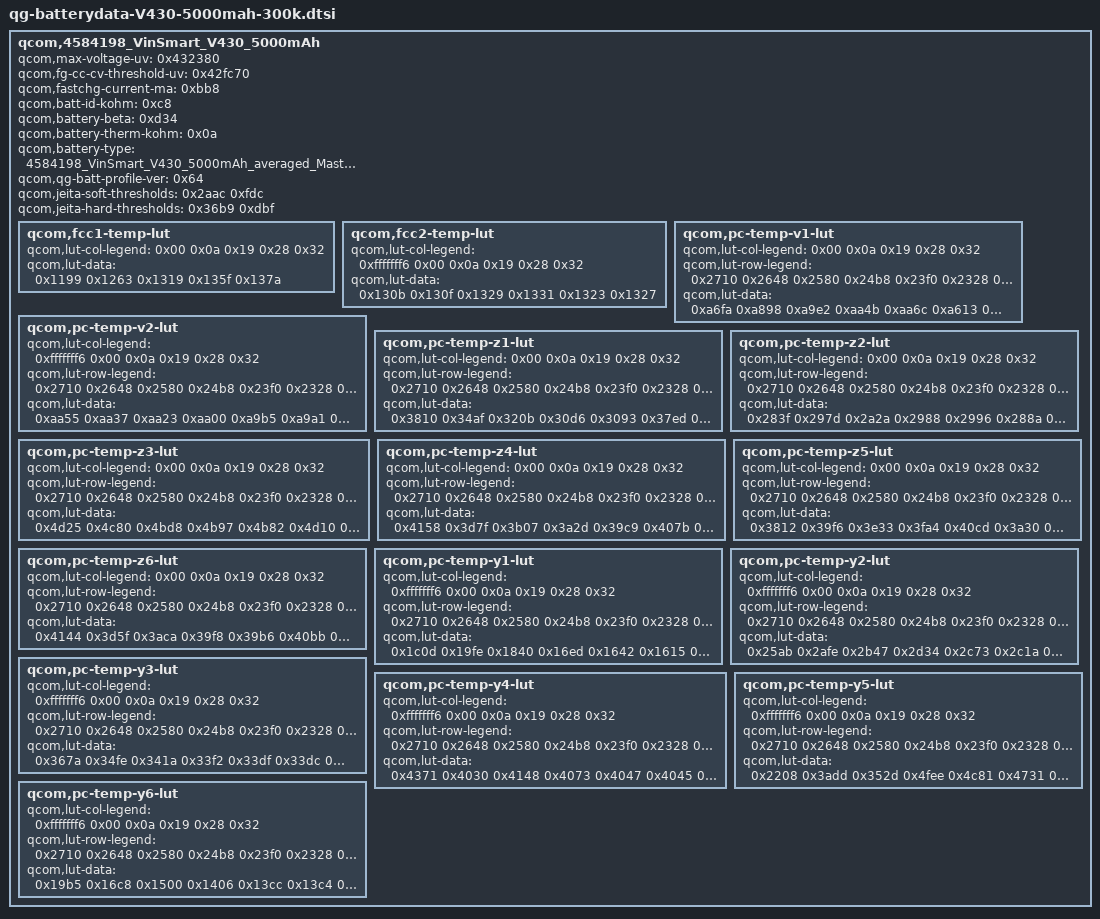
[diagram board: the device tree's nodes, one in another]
qcom,4584198_VinSmart_V430_5000mAh {
	qcom,max-voltage-uv = <0x432380>;
	qcom,fg-cc-cv-threshold-uv = <0x42fc70>;
	qcom,fastchg-current-ma = <0xbb8>;
	qcom,batt-id-kohm = <0xc8>;
	qcom,battery-beta = <0xd34>;
	qcom,battery-therm-kohm = <0x0a>;
	qcom,battery-type = "4584198_VinSmart_V430_5000mAh_averaged_MasterSlave_Jun3rd2020";
	qcom,qg-batt-profile-ver = <0x64>;
	qcom,jeita-soft-thresholds = <0x2aac 0xfdc>;
	qcom,jeita-hard-thresholds = <0x36b9 0xdbf>;

	qcom,fcc1-temp-lut {
		qcom,lut-col-legend = <0x00 0x0a 0x19 0x28 0x32>;
		qcom,lut-data = <0x1199 0x1263 0x1319 0x135f 0x137a>;
	};

	qcom,fcc2-temp-lut {
		qcom,lut-col-legend = <0xfffffff6 0x00 0x0a 0x19 0x28 0x32>;
		qcom,lut-data = <0x130b 0x130f 0x1329 0x1331 0x1323 0x1327>;
	};

	qcom,pc-temp-v1-lut {
		qcom,lut-col-legend = <0x00 0x0a 0x19 0x28 0x32>;
		qcom,lut-row-legend = <0x2710 0x2648 0x2580 0x24b8 0x23f0 0x2328 0x2260 0x2198 0x20d0 0x2008 0x1f40 0x1e78 0x1db0 0x1ce8 0x1c20 0x1b58 0x1a90 0x19c8 0x1900 0x1838 0x1770 0x16a8 0x15e0 0x1518 0x1450 0x1388 0x12c0 0x11f8 0x1130 0x1068 0xfa0 0xed8 0xe10 0xd48 0xc80 0xbb8 0xaf0 0xa28 0x960 0x898 0x7d0 0x708 0x640 0x578 0x4b0 0x3e8 0x384 0x320 0x2bc 0x258 0x1f4 0x190 0x12c 0xc8 0x64 0x00>;
		qcom,lut-data = <0xa6fa 0xa898 0xa9e2 0xaa4b 0xaa6c 0xa613 0xa7ac 0xa8ef 0xa95b 0xa981 0xa533 0xa6c5 0xa7fe 0xa86d 0xa893 0xa45c 0xa5e2 0xa70e 0xa780 0xa7a7 0xa38b 0xa503 0xa623 0xa695 0xa6c0 0xa2c2 0xa429 0xa53b 0xa5ac 0xa5d8 0xa204 0xa355 0xa458 0xa4c6 0xa4f2 0xa152 0xa288 0xa37a 0xa3e3 0xa40e 0xa0a2 0xa1c5 0xa2a1 0xa305 0xa32e 0x9fe5 0xa110 0xa1cd 0xa22a 0xa252 0x9f15 0xa056 0xa105 0xa153 0xa179 0x9e3a 0x9f87 0xa044 0xa080 0xa0a2 0x9d50 0x9ea7 0x9f79 0x9fb1 0x9fd0 0x9c68 0x9dcc 0x9e9c 0x9ee7 0x9f06 0x9bb2 0x9cf2 0x9dc5 0x9e22 0x9e40 0x9b33 0x9c2c 0x9d0a 0x9d67 0x9d84 0x9ace 0x9b97 0x9c60 0x9cbd 0x9cd6 0x9a67 0x9b26 0x9bbf 0x9c13 0x9c2c 0x99ff 0x9ab8 0x9b2a 0x9b59 0x9b75 0x9997 0x9a3b 0x9a91 0x9a91 0x9aaf 0x9934 0x99b8 0x99d3 0x99d3 0x99ee 0x98d2 0x992f 0x98f2 0x991d 0x9938 0x9875 0x98a2 0x9832 0x9876 0x988d 0x981f 0x9812 0x979c 0x97dc 0x97ef 0x97ce 0x9782 0x971f 0x974d 0x975c 0x9781 0x96ec 0x96be 0x96d5 0x96de 0x9736 0x9672 0x9670 0x9673 0x9677 0x96ef 0x9624 0x962c 0x961c 0x961c 0x96a8 0x95e7 0x95ea 0x95ca 0x95c6 0x9661 0x95b8 0x95ad 0x957d 0x9575 0x961e 0x9592 0x9575 0x953a 0x952d 0x95e4 0x9574 0x953f 0x9502 0x94ec 0x95b1 0x9558 0x950e 0x94cf 0x94b2 0x9582 0x9540 0x94e2 0x949a 0x9478 0x9556 0x9526 0x94bb 0x9467 0x9442 0x952c 0x9506 0x9492 0x9434 0x940a 0x9502 0x94de 0x9469 0x9404 0x93d1 0x94d8 0x94ac 0x943a 0x93d1 0x9394 0x94ab 0x9465 0x93f5 0x938a 0x9348 0x946f 0x940c 0x9398 0x932e 0x92ec 0x940b 0x93a5 0x9330 0x92c6 0x9284 0x938c 0x9328 0x92b9 0x9254 0x9210 0x9302 0x929c 0x9234 0x91d4 0x918e 0x9277 0x9201 0x9199 0x9139 0x90f6 0x91f9 0x9187 0x911c 0x90bf 0x9080 0x9191 0x9137 0x90cd 0x9072 0x9036 0x916b 0x911a 0x90b9 0x905b 0x9021 0x9148 0x9107 0x90a6 0x904c 0x9010 0x9123 0x90f4 0x9097 0x9039 0x8ffd 0x90d6 0x90b1 0x905f 0x9000 0x8fbd 0x8ffa 0x8fd2 0x8f6f 0x8efd 0x8ea5 0x8e55 0x8e14 0x8dc3 0x8d50 0x8cf8 0x8c2a 0x8bf0 0x8ba0 0x8b25 0x8acb 0x894d 0x8911 0x88b6 0x8835 0x87db 0x8498 0x846c 0x8420 0x83a9 0x8357 0x7530 0x7530 0x7530 0x7530 0x7530>;
	};

	qcom,pc-temp-v2-lut {
		qcom,lut-col-legend = <0xfffffff6 0x00 0x0a 0x19 0x28 0x32>;
		qcom,lut-row-legend = <0x2710 0x2648 0x2580 0x24b8 0x23f0 0x2328 0x2260 0x2198 0x20d0 0x2008 0x1f40 0x1e78 0x1db0 0x1ce8 0x1c20 0x1b58 0x1a90 0x19c8 0x1900 0x1838 0x1770 0x16a8 0x15e0 0x1518 0x1450 0x1388 0x12c0 0x11f8 0x1130 0x1068 0xfa0 0xed8 0xe10 0xd48 0xc80 0xbb8 0xaf0 0xa28 0x960 0x898 0x7d0 0x708 0x640 0x578 0x4b0 0x3e8 0x384 0x320 0x2bc 0x258 0x1f4 0x190 0x12c 0xc8 0x64 0x00>;
		qcom,lut-data = <0xaa55 0xaa37 0xaa23 0xaa00 0xa9b5 0xa9a1 0xa8a4 0xa8ab 0xa8d5 0xa8d5 0xa89b 0xa893 0xa721 0xa747 0xa7a1 0xa7bd 0xa790 0xa78f 0xa5d5 0xa611 0xa68c 0xa6bb 0xa696 0xa699 0xa4b8 0xa503 0xa595 0xa5cd 0xa5ad 0xa5b1 0xa3b3 0xa40c 0xa4a9 0xa4e7 0xa4cb 0xa4ce 0xa29d 0xa322 0xa3bf 0xa403 0xa3e7 0xa3eb 0xa198 0xa248 0xa2d9 0xa323 0xa307 0xa30b 0xa10f 0xa182 0xa1f6 0xa246 0xa22b 0xa22f 0xa0dc 0xa0d8 0xa10d 0xa16a 0xa152 0xa157 0xa0a5 0xa02d 0xa037 0xa096 0xa07e 0xa083 0x9fb0 0x9f62 0x9f92 0x9fda 0x9fb1 0x9fb4 0x9d96 0x9e7c 0x9f04 0x9f29 0x9eea 0x9ee9 0x9bf7 0x9d7f 0x9e44 0x9e61 0x9e28 0x9e25 0x9b0b 0x9c4d 0x9d0a 0x9d69 0x9d65 0x9d67 0x9a48 0x9b24 0x9bc9 0x9c7a 0x9ca7 0x9cae 0x998c 0x9a51 0x9af7 0x9bcc 0x9bf8 0x9bfe 0x98dd 0x99ac 0x9a56 0x9b3f 0x9b52 0x9b56 0x9831 0x9909 0x99b1 0x9a9a 0x9a9f 0x9aa2 0x977c 0x9859 0x98f8 0x99bf 0x99cd 0x99d4 0x96d0 0x97a8 0x9842 0x98db 0x98f6 0x9903 0x9648 0x96f3 0x97a3 0x9820 0x983a 0x9849 0x95d5 0x9631 0x9714 0x977c 0x978f 0x979c 0x9575 0x9599 0x9691 0x96ec 0x96fb 0x9704 0x9527 0x9540 0x961a 0x9673 0x967f 0x9686 0x94e3 0x94fd 0x95ab 0x9606 0x9612 0x9617 0x94a5 0x94c2 0x953b 0x95a4 0x95af 0x95b3 0x946c 0x948e 0x94ca 0x9549 0x9555 0x9557 0x9436 0x945e 0x946e 0x94f7 0x9503 0x9503 0x93ff 0x9430 0x942d 0x94ab 0x94b9 0x94b8 0x93c7 0x9404 0x93fb 0x9465 0x9476 0x9474 0x9391 0x93d8 0x93d1 0x9422 0x9434 0x9431 0x935d 0x93ab 0x93b1 0x93e4 0x93f6 0x93f4 0x9328 0x937d 0x9391 0x93a7 0x93b5 0x93b2 0x92f1 0x934b 0x936c 0x9371 0x936a 0x935d 0x92b9 0x9316 0x9343 0x933c 0x9318 0x92fa 0x9280 0x92db 0x9315 0x9301 0x92c7 0x929b 0x9249 0x9297 0x92de 0x92c2 0x9278 0x9243 0x9210 0x924b 0x929a 0x927c 0x9228 0x91ed 0x91d7 0x91fa 0x9240 0x9233 0x91d9 0x919c 0x919b 0x91a3 0x91ce 0x91e4 0x918a 0x914e 0x915b 0x914d 0x9161 0x9184 0x912f 0x90f3 0x9115 0x90fe 0x90f8 0x9105 0x90b5 0x9079 0x90c8 0x90b3 0x909a 0x908d 0x9043 0x9008 0x906d 0x906a 0x904c 0x9029 0x8fea 0x8fb1 0x8ffc 0x9012 0x8ff6 0x8ff8 0x8fc4 0x8f90 0x8fb8 0x8fdd 0x8fc4 0x8fe6 0x8fb7 0x8f84 0x8f52 0x8f9f 0x8f88 0x8fcf 0x8fa4 0x8f73 0x8ecd 0x8f52 0x8f3b 0x8faa 0x8f86 0x8f56 0x8e24 0x8ed5 0x8eb4 0x8f4d 0x8f29 0x8ef2 0x8d26 0x8dfc 0x8dd3 0x8e4d 0x8e0f 0x8dbf 0x8bb3 0x8c7b 0x8c6d 0x8c7d 0x8c3e 0x8bec 0x899f 0x8a43 0x8a43 0x8a18 0x89e9 0x898e 0x8673 0x8700 0x8723 0x86db 0x86bb 0x865d 0x8122 0x81dc 0x8227 0x81f1 0x821e 0x81c3 0x743f 0x73d8 0x73b0 0x7393 0x7378 0x736a>;
	};

	qcom,pc-temp-z1-lut {
		qcom,lut-col-legend = <0x00 0x0a 0x19 0x28 0x32>;
		qcom,lut-row-legend = <0x2710 0x2648 0x2580 0x24b8 0x23f0 0x2328 0x2260 0x2198 0x20d0 0x2008 0x1f40 0x1e78 0x1db0 0x1ce8 0x1c20 0x1b58 0x1a90 0x19c8 0x1900 0x1838 0x1770 0x16a8 0x15e0 0x1518 0x1450 0x1388 0x12c0 0x11f8 0x1130 0x1068 0xfa0 0xed8 0xe10 0xd48 0xc80 0xbb8 0xaf0 0xa28 0x960 0x898 0x7d0 0x708 0x640 0x578 0x4b0 0x3e8 0x384 0x320 0x2bc 0x258 0x1f4 0x190 0x12c 0xc8 0x64 0x00>;
		qcom,lut-data = <0x3810 0x34af 0x320b 0x30d6 0x3093 0x37ed 0x34bd 0x3201 0x30d7 0x3099 0x37d6 0x34c2 0x3200 0x30da 0x30a1 0x37d1 0x34b9 0x3200 0x30da 0x30a3 0x37cd 0x34aa 0x31fe 0x30da 0x30a2 0x37cc 0x34a6 0x31f8 0x30da 0x30a4 0x37cf 0x34a9 0x31f3 0x30d9 0x30a8 0x37d1 0x34ad 0x31f0 0x30da 0x30ab 0x37cf 0x34ad 0x31ee 0x30dc 0x30b0 0x37c5 0x34a7 0x31ed 0x30e0 0x30b5 0x37b6 0x34a0 0x31f0 0x30e2 0x30b8 0x37b1 0x3493 0x31f3 0x30e2 0x30ba 0x37b0 0x347c 0x31f3 0x30e2 0x30bc 0x379c 0x346f 0x31ea 0x30e3 0x30be 0x3784 0x3470 0x31e2 0x30e4 0x30c0 0x3768 0x3477 0x31e3 0x30e6 0x30c2 0x3750 0x347f 0x31e9 0x30e9 0x30c5 0x374d 0x3489 0x31f0 0x30ec 0x30c8 0x374a 0x3493 0x31f9 0x30ef 0x30cb 0x3746 0x349c 0x3203 0x30f3 0x30ce 0x3741 0x34a4 0x3209 0x30f6 0x30d1 0x3736 0x34aa 0x320d 0x30fa 0x30d5 0x372b 0x34b1 0x3211 0x30fe 0x30d9 0x372a 0x34b7 0x3215 0x3101 0x30dd 0x372e 0x34be 0x3219 0x3105 0x30e2 0x3732 0x34c8 0x321e 0x3108 0x30e6 0x373b 0x34d0 0x3223 0x310e 0x30eb 0x374c 0x34d4 0x3229 0x3115 0x30ee 0x375b 0x34da 0x3230 0x311a 0x30f2 0x3766 0x34e1 0x3237 0x311e 0x30f6 0x3770 0x34ed 0x323d 0x3123 0x30fa 0x377b 0x34f9 0x3241 0x3127 0x30fe 0x3788 0x34ff 0x3245 0x312b 0x3102 0x3794 0x3505 0x324b 0x312f 0x3106 0x379c 0x350b 0x3251 0x3134 0x3109 0x37a1 0x3511 0x3257 0x3138 0x310d 0x37a8 0x3517 0x3260 0x313d 0x3110 0x37bb 0x351c 0x3268 0x3143 0x3114 0x37d8 0x3524 0x3270 0x3147 0x3118 0x37e8 0x352c 0x3277 0x314b 0x311d 0x37e4 0x3532 0x327d 0x314f 0x3121 0x37dc 0x3539 0x3282 0x3155 0x3125 0x37d9 0x354e 0x3287 0x315b 0x3128 0x37da 0x3570 0x3291 0x3161 0x312c 0x37c9 0x3560 0x329c 0x3166 0x3130 0x37da 0x3559 0x32a6 0x3169 0x3132 0x3804 0x355a 0x32a1 0x316c 0x3132 0x37cf 0x3569 0x32a3 0x316b 0x3133 0x37d6 0x356a 0x32a7 0x316e 0x3135 0x37df 0x356b 0x32ab 0x3174 0x3139 0x37f6 0x3574 0x32b7 0x317b 0x313f 0x3802 0x3586 0x32c6 0x3185 0x3147 0x37ff 0x3595 0x32e0 0x3192 0x3153 0x3803 0x35d5 0x3301 0x31a8 0x3163 0x3803 0x35d5 0x3301 0x31a8 0x3163 0x3803 0x35d5 0x3301 0x31a8 0x3163>;
	};

	qcom,pc-temp-z2-lut {
		qcom,lut-col-legend = <0x00 0x0a 0x19 0x28 0x32>;
		qcom,lut-row-legend = <0x2710 0x2648 0x2580 0x24b8 0x23f0 0x2328 0x2260 0x2198 0x20d0 0x2008 0x1f40 0x1e78 0x1db0 0x1ce8 0x1c20 0x1b58 0x1a90 0x19c8 0x1900 0x1838 0x1770 0x16a8 0x15e0 0x1518 0x1450 0x1388 0x12c0 0x11f8 0x1130 0x1068 0xfa0 0xed8 0xe10 0xd48 0xc80 0xbb8 0xaf0 0xa28 0x960 0x898 0x7d0 0x708 0x640 0x578 0x4b0 0x3e8 0x384 0x320 0x2bc 0x258 0x1f4 0x190 0x12c 0xc8 0x64 0x00>;
		qcom,lut-data = <0x283f 0x297d 0x2a2a 0x2988 0x2996 0x288a 0x2967 0x2a29 0x29cf 0x2993 0x28ba 0x2955 0x2a29 0x29fa 0x29a8 0x28c7 0x2946 0x2a1e 0x2a07 0x29ac 0x28ad 0x2937 0x2a0d 0x2a0e 0x29ab 0x288a 0x2928 0x29f9 0x2a09 0x29a3 0x287d 0x2919 0x29e1 0x29e5 0x2985 0x287e 0x290a 0x29cf 0x29c8 0x296a 0x287f 0x2900 0x29bf 0x29c1 0x295a 0x2881 0x28f8 0x29b6 0x29b8 0x2930 0x2884 0x28f0 0x29c4 0x29b3 0x2913 0x2886 0x28ea 0x29e5 0x29bd 0x291f 0x287d 0x28e4 0x29fa 0x29c9 0x2931 0x2862 0x28e3 0x2a04 0x29cb 0x293e 0x2845 0x28e5 0x2a0a 0x29cc 0x294c 0x282a 0x28e8 0x2a09 0x29cb 0x295a 0x2814 0x28f1 0x2a07 0x29af 0x2970 0x280c 0x2909 0x2a0a 0x298f 0x298b 0x2809 0x292a 0x2a4d 0x29bd 0x29a1 0x2808 0x294e 0x2a99 0x2a4c 0x29b4 0x2803 0x297a 0x2a97 0x2a94 0x29c8 0x27fc 0x29a9 0x2a74 0x2a91 0x2a07 0x27f7 0x29e5 0x2a61 0x2a8c 0x2a69 0x27f8 0x2a16 0x2a70 0x2aae 0x2aa1 0x27ff 0x2a1e 0x2a8c 0x2b00 0x2ade 0x280b 0x2a1c 0x2aa1 0x2b24 0x2ae5 0x2822 0x2a1b 0x2ab9 0x2aee 0x2a91 0x2847 0x2a27 0x2ac9 0x2a9f 0x2a23 0x286c 0x2a3f 0x2ace 0x2a71 0x29ce 0x2893 0x2a54 0x2ad2 0x2a47 0x296e 0x28b9 0x2a66 0x2adb 0x2a27 0x293a 0x28cf 0x2a77 0x2af1 0x2a08 0x293a 0x28de 0x2a84 0x2b02 0x29f2 0x2942 0x28e7 0x2a90 0x2b04 0x2a03 0x2957 0x28eb 0x2a9c 0x2b05 0x2a4f 0x298f 0x28ee 0x2aac 0x2b09 0x2a94 0x29cf 0x28ef 0x2ac3 0x2b1e 0x2ac2 0x2a11 0x2869 0x2ad8 0x2b3b 0x2aeb 0x2a4e 0x2734 0x2aeb 0x2b5a 0x2b18 0x2a6b 0x269c 0x2afd 0x2b7f 0x2b4d 0x2a81 0x2774 0x2b09 0x2b94 0x2b65 0x2a90 0x285a 0x2b13 0x2b9f 0x2b5b 0x2a98 0x280e 0x2b1d 0x2ba0 0x2b50 0x2a9c 0x273d 0x2b2d 0x2b91 0x2b4c 0x2ab5 0x25fa 0x2bf8 0x2bcf 0x2b34 0x2aa9 0x260e 0x2c28 0x2bdc 0x2b07 0x2aa3 0x26b7 0x2c36 0x2bc5 0x2b06 0x2a9e 0x26a8 0x2c5e 0x2bcc 0x2b11 0x2a98 0x26ce 0x2cdf 0x2c27 0x2b19 0x2af5 0x2713 0x2d0b 0x2c3e 0x2b86 0x2b8f 0x26b7 0x2c9f 0x2c2c 0x2b6d 0x2a76 0x2633 0x2c13 0x2baf 0x2a8a 0x29c7 0x2615 0x2b7c 0x2bed 0x2a4f 0x2979 0x2554 0x29f6 0x2b6a 0x29eb 0x2939 0x2554 0x29f6 0x2b6a 0x29eb 0x2939 0x2554 0x29f6 0x2b6a 0x29eb 0x2939>;
	};

	qcom,pc-temp-z3-lut {
		qcom,lut-col-legend = <0x00 0x0a 0x19 0x28 0x32>;
		qcom,lut-row-legend = <0x2710 0x2648 0x2580 0x24b8 0x23f0 0x2328 0x2260 0x2198 0x20d0 0x2008 0x1f40 0x1e78 0x1db0 0x1ce8 0x1c20 0x1b58 0x1a90 0x19c8 0x1900 0x1838 0x1770 0x16a8 0x15e0 0x1518 0x1450 0x1388 0x12c0 0x11f8 0x1130 0x1068 0xfa0 0xed8 0xe10 0xd48 0xc80 0xbb8 0xaf0 0xa28 0x960 0x898 0x7d0 0x708 0x640 0x578 0x4b0 0x3e8 0x384 0x320 0x2bc 0x258 0x1f4 0x190 0x12c 0xc8 0x64 0x00>;
		qcom,lut-data = <0x4d25 0x4c80 0x4bd8 0x4b97 0x4b82 0x4d10 0x4c8e 0x4be9 0x4ba7 0x4b97 0x4cfe 0x4c97 0x4bf4 0x4bb1 0x4b9f 0x4cf0 0x4c9a 0x4bfc 0x4bb6 0x4ba1 0x4ce2 0x4c99 0x4bff 0x4bb9 0x4ba3 0x4cd8 0x4c96 0x4bff 0x4bba 0x4ba4 0x4cd3 0x4c90 0x4bfd 0x4bba 0x4ba5 0x4cd3 0x4c89 0x4bfa 0x4bb9 0x4ba6 0x4cd3 0x4c81 0x4bf3 0x4bb6 0x4ba5 0x4cd5 0x4c74 0x4bec 0x4baf 0x4ba0 0x4cdc 0x4c6a 0x4be9 0x4baa 0x4b9b 0x4ce2 0x4c69 0x4be6 0x4ba8 0x4b99 0x4ce2 0x4c6a 0x4be4 0x4ba6 0x4b97 0x4cdf 0x4c6a 0x4be2 0x4ba5 0x4b95 0x4cd9 0x4c65 0x4be0 0x4ba4 0x4b94 0x4ccc 0x4c5b 0x4bda 0x4ba2 0x4b92 0x4cbb 0x4c4d 0x4bcf 0x4b9b 0x4b8e 0x4cac 0x4c37 0x4bcb 0x4b95 0x4b89 0x4c9f 0x4c29 0x4bcb 0x4b98 0x4b88 0x4c93 0x4c29 0x4bcc 0x4b9f 0x4b8a 0x4c87 0x4c2a 0x4bcf 0x4ba2 0x4b8b 0x4c7b 0x4c2c 0x4bd6 0x4b9d 0x4b8b 0x4c6f 0x4c31 0x4bda 0x4b97 0x4b8c 0x4c66 0x4c38 0x4bd5 0x4b99 0x4b90 0x4c5f 0x4c3a 0x4bcf 0x4ba1 0x4b99 0x4c5c 0x4c3b 0x4bcc 0x4ba8 0x4ba0 0x4c62 0x4c3b 0x4bca 0x4bad 0x4ba5 0x4c70 0x4c3a 0x4bc9 0x4bb2 0x4ba9 0x4c81 0x4c38 0x4bcb 0x4bb4 0x4ba9 0x4c98 0x4c36 0x4bcf 0x4bb6 0x4ba6 0x4cae 0x4c33 0x4bd3 0x4bb7 0x4ba3 0x4cb2 0x4c31 0x4bd8 0x4bb1 0x4b9e 0x4cad 0x4c2d 0x4bdb 0x4ba9 0x4b99 0x4ca6 0x4c27 0x4bd9 0x4ba5 0x4b94 0x4c9e 0x4c22 0x4bd5 0x4ba2 0x4b8e 0x4c92 0x4c1f 0x4bd1 0x4b9f 0x4b89 0x4c80 0x4c1c 0x4bce 0x4b9b 0x4b87 0x4c4c 0x4c1a 0x4bcb 0x4b97 0x4b86 0x4bf7 0x4c18 0x4bc8 0x4b96 0x4b85 0x4bd0 0x4c16 0x4bc6 0x4b95 0x4b85 0x4bf0 0x4c13 0x4bc4 0x4b95 0x4b84 0x4c0b 0x4c0e 0x4bc3 0x4b93 0x4b86 0x4bef 0x4c0a 0x4bc1 0x4b92 0x4b87 0x4bb2 0x4c06 0x4bbe 0x4b93 0x4b88 0x4b42 0x4be5 0x4bb3 0x4b8e 0x4b85 0x4b42 0x4bd8 0x4bae 0x4b8a 0x4b7f 0x4b3f 0x4bd0 0x4ba7 0x4b87 0x4b79 0x4b40 0x4ba5 0x4ba6 0x4b7f 0x4b75 0x4b3f 0x4b6f 0x4b8e 0x4b7d 0x4b6f 0x4b3e 0x4b6e 0x4b92 0x4b7a 0x4b69 0x4b40 0x4b8f 0x4b9b 0x4b7c 0x4b7f 0x4b41 0x4bca 0x4b9e 0x4b84 0x4b85 0x4b41 0x4bbd 0x4b81 0x4b85 0x4b88 0x4b45 0x4b8e 0x4b7d 0x4b86 0x4b86 0x4b45 0x4b8e 0x4b7d 0x4b86 0x4b86 0x4b45 0x4b8e 0x4b7d 0x4b86 0x4b86>;
	};

	qcom,pc-temp-z4-lut {
		qcom,lut-col-legend = <0x00 0x0a 0x19 0x28 0x32>;
		qcom,lut-row-legend = <0x2710 0x2648 0x2580 0x24b8 0x23f0 0x2328 0x2260 0x2198 0x20d0 0x2008 0x1f40 0x1e78 0x1db0 0x1ce8 0x1c20 0x1b58 0x1a90 0x19c8 0x1900 0x1838 0x1770 0x16a8 0x15e0 0x1518 0x1450 0x1388 0x12c0 0x11f8 0x1130 0x1068 0xfa0 0xed8 0xe10 0xd48 0xc80 0xbb8 0xaf0 0xa28 0x960 0x898 0x7d0 0x708 0x640 0x578 0x4b0 0x3e8 0x384 0x320 0x2bc 0x258 0x1f4 0x190 0x12c 0xc8 0x64 0x00>;
		qcom,lut-data = <0x4158 0x3d7f 0x3b07 0x3a2d 0x39c9 0x407b 0x3cce 0x3acb 0x3a16 0x39eb 0x3fb4 0x3c39 0x3a8f 0x39fe 0x39dc 0x3f06 0x3bc3 0x3a52 0x39e3 0x39cc 0x3e6f 0x3b60 0x3a20 0x39c9 0x39b8 0x3dea 0x3b10 0x39f8 0x39b2 0x39a6 0x3d72 0x3ace 0x39d8 0x399e 0x3996 0x3d01 0x3a97 0x39bf 0x398d 0x3988 0x3c9a 0x3a6b 0x39ac 0x397f 0x397b 0x3c40 0x3a47 0x399c 0x3974 0x3971 0x3bf3 0x3a26 0x398c 0x396b 0x3969 0x3bba 0x3a04 0x397d 0x3965 0x3963 0x3b95 0x39e3 0x3977 0x395f 0x395d 0x3b77 0x39cf 0x3976 0x3959 0x3958 0x3b55 0x39c7 0x3975 0x3954 0x3953 0x3b22 0x39c1 0x3971 0x3950 0x394e 0x3aec 0x39b7 0x3968 0x394c 0x3949 0x3ac8 0x39a5 0x3963 0x3949 0x3944 0x3aaf 0x3997 0x3960 0x394e 0x3948 0x3a9e 0x3991 0x395e 0x395f 0x395c 0x3a93 0x398c 0x396e 0x3974 0x3972 0x3a8c 0x398b 0x39a5 0x3994 0x3988 0x3a86 0x3991 0x39cf 0x39ae 0x399a 0x3a7c 0x399f 0x39e3 0x39b1 0x399b 0x3a71 0x39b5 0x39ef 0x39b0 0x3998 0x3a62 0x39e0 0x39ee 0x39ad 0x3993 0x3a4b 0x39fc 0x39df 0x399c 0x3984 0x3a2e 0x39fb 0x39cd 0x3985 0x396e 0x3a12 0x39f6 0x39bb 0x3976 0x3962 0x39f3 0x39f0 0x39a8 0x3969 0x395a 0x39d8 0x39e2 0x3999 0x3960 0x3955 0x39c9 0x39d0 0x398a 0x395b 0x394f 0x39c2 0x39c1 0x3981 0x3957 0x394b 0x39bc 0x39b1 0x397d 0x3957 0x394b 0x39b8 0x39a4 0x397a 0x3958 0x394c 0x39b5 0x3999 0x3979 0x3958 0x394e 0x39b3 0x3991 0x3978 0x3959 0x3950 0x39d3 0x398e 0x3977 0x395b 0x3952 0x3a1a 0x398e 0x397a 0x395e 0x3956 0x3a3d 0x398e 0x3980 0x3966 0x395d 0x3a0e 0x398e 0x3982 0x396a 0x3961 0x39e3 0x398d 0x397c 0x3965 0x395d 0x39f9 0x398b 0x3975 0x3962 0x3959 0x3a20 0x3983 0x3973 0x3964 0x395e 0x3a4a 0x3967 0x395e 0x395a 0x3956 0x3a44 0x3960 0x394b 0x3947 0x3946 0x3a3c 0x395d 0x3944 0x3940 0x3940 0x3a35 0x3981 0x393b 0x3937 0x3935 0x3a2e 0x39b2 0x3945 0x392a 0x3929 0x3a2b 0x39b0 0x393d 0x392b 0x392b 0x3a37 0x3999 0x3949 0x3946 0x393a 0x3a59 0x3973 0x3954 0x3946 0x393c 0x3a74 0x3991 0x3974 0x3948 0x393d 0x3a94 0x39d7 0x397d 0x394a 0x3941 0x3a94 0x39d7 0x397d 0x394a 0x3941 0x3a94 0x39d7 0x397d 0x394a 0x3941>;
	};

	qcom,pc-temp-z5-lut {
		qcom,lut-col-legend = <0x00 0x0a 0x19 0x28 0x32>;
		qcom,lut-row-legend = <0x2710 0x2648 0x2580 0x24b8 0x23f0 0x2328 0x2260 0x2198 0x20d0 0x2008 0x1f40 0x1e78 0x1db0 0x1ce8 0x1c20 0x1b58 0x1a90 0x19c8 0x1900 0x1838 0x1770 0x16a8 0x15e0 0x1518 0x1450 0x1388 0x12c0 0x11f8 0x1130 0x1068 0xfa0 0xed8 0xe10 0xd48 0xc80 0xbb8 0xaf0 0xa28 0x960 0x898 0x7d0 0x708 0x640 0x578 0x4b0 0x3e8 0x384 0x320 0x2bc 0x258 0x1f4 0x190 0x12c 0xc8 0x64 0x00>;
		qcom,lut-data = <0x3812 0x39f6 0x3e33 0x3fa4 0x40cd 0x3a30 0x3b9c 0x4128 0x4564 0x4937 0x3c20 0x3d49 0x4488 0x4a38 0x4ea7 0x3ddb 0x3f00 0x4846 0x4e10 0x513f 0x3f62 0x40c7 0x4bd7 0x5151 0x5387 0x40ba 0x4293 0x4f7d 0x5477 0x5601 0x41ec 0x448e 0x52bb 0x581c 0x5a2a 0x42f8 0x467b 0x5461 0x5afb 0x5e55 0x4415 0x47f2 0x5528 0x5bb8 0x5fe4 0x45c6 0x48f0 0x5616 0x5b9c 0x6098 0x486d 0x4a4c 0x5993 0x5be3 0x615f 0x4ab6 0x4f5d 0x6007 0x5e91 0x6359 0x4ba7 0x5963 0x6594 0x62bb 0x672f 0x4c1e 0x5f0f 0x6aec 0x67cb 0x6c4f 0x4c47 0x5f8a 0x6e2b 0x6daa 0x734d 0x4c3e 0x5f2a 0x6bee 0x6f33 0x76b0 0x4c0b 0x5e87 0x663d 0x6ae7 0x7551 0x4bb6 0x5d0d 0x6499 0x6686 0x7306 0x4b17 0x5c44 0x71d1 0x72da 0x7522 0x4a31 0x61ab 0x860d 0x947d 0x7d90 0x48f8 0x70a3 0x9799 0xa105 0x813c 0x46f2 0x8235 0xa963 0x859c 0x72e6 0x44fa 0x9be2 0xafcf 0x64e3 0x5fa0 0x43d6 0xb424 0x9c27 0x5c05 0x5a7b 0x4306 0xbc2a 0x7e8d 0x57d6 0x583f 0x42b7 0xbfac 0x6f47 0x56c5 0x576e 0x449b 0xc126 0x6503 0x5871 0x5a61 0x4976 0xbd5a 0x60aa 0x5bdd 0x6070 0x50c8 0xb410 0x6236 0x63a0 0x66c8 0x6175 0xac6a 0x6645 0x7354 0x6e5d 0x73f7 0xa708 0x6d3b 0x7bed 0x74e7 0x7bd3 0xa277 0x7d98 0x7d3d 0x7b11 0x7fa8 0x9dee 0x8d0b 0x7e35 0x8016 0x81c7 0x9791 0x95c3 0x8301 0x80d8 0x80ba 0x93ab 0x9c3e 0x8e7b 0x8045 0x7b1d 0x959e 0x9dd9 0x93dc 0x7f64 0x72bb 0x9a69 0x9dc9 0x8f46 0x7e12 0x6014 0x9dd6 0x9d78 0x8736 0x7bed 0x43e8 0xa21e 0x9985 0x8042 0x779c 0x3770 0xa5cb 0x9010 0x785d 0x6e1f 0x4592 0xa2cf 0x8a37 0x71bb 0x68b4 0x51fa 0x96e4 0x869b 0x6c3c 0x6911 0x4f98 0x931f 0x82c3 0x68d5 0x696a 0x47ea 0x9369 0x7bcc 0x67e9 0x68ee 0x2fd8 0x89c9 0x7e15 0x6559 0x661b 0x2fb9 0x73e4 0x8032 0x64ac 0x5f4a 0x2f57 0x684e 0x712e 0x633f 0x5631 0x2f51 0x5076 0x77b7 0x5d78 0x58ea 0x2f35 0x3645 0x51e1 0x670d 0x5d6a 0x2f3c 0x364f 0x59ab 0x6292 0x51b6 0x2fb9 0x4052 0x5bcf 0x4da2 0x5aa6 0x2fd2 0x53ff 0x5130 0x4d7f 0x5850 0x2ee4 0x456b 0x3c54 0x4a0f 0x5528 0x2e35 0x35b9 0x395e 0x46f9 0x4b4c 0x2e35 0x35b9 0x395e 0x46f9 0x4b4c 0x2e35 0x35b9 0x395e 0x46f9 0x4b4c>;
	};

	qcom,pc-temp-z6-lut {
		qcom,lut-col-legend = <0x00 0x0a 0x19 0x28 0x32>;
		qcom,lut-row-legend = <0x2710 0x2648 0x2580 0x24b8 0x23f0 0x2328 0x2260 0x2198 0x20d0 0x2008 0x1f40 0x1e78 0x1db0 0x1ce8 0x1c20 0x1b58 0x1a90 0x19c8 0x1900 0x1838 0x1770 0x16a8 0x15e0 0x1518 0x1450 0x1388 0x12c0 0x11f8 0x1130 0x1068 0xfa0 0xed8 0xe10 0xd48 0xc80 0xbb8 0xaf0 0xa28 0x960 0x898 0x7d0 0x708 0x640 0x578 0x4b0 0x3e8 0x384 0x320 0x2bc 0x258 0x1f4 0x190 0x12c 0xc8 0x64 0x00>;
		qcom,lut-data = <0x4144 0x3d5f 0x3aca 0x39f8 0x39b6 0x40bb 0x3d07 0x3ab4 0x39f5 0x39cd 0x4041 0x3cbb 0x3a9d 0x39f1 0x39ce 0x3fd8 0x3c7b 0x3a84 0x39eb 0x39cc 0x3f7d 0x3c45 0x3a6e 0x39e0 0x39c4 0x3f2f 0x3c16 0x3a5a 0x39d6 0x39bc 0x3eea 0x3bed 0x3a49 0x39ce 0x39b7 0x3ead 0x3bca 0x3a3a 0x39c6 0x39b2 0x3e75 0x3bac 0x3a2d 0x39be 0x39ac 0x3e40 0x3b91 0x3a22 0x39b7 0x39a6 0x3e10 0x3b79 0x3a19 0x39b1 0x39a1 0x3de9 0x3b5f 0x3a12 0x39ac 0x399d 0x3dca 0x3b46 0x3a0d 0x39a9 0x399a 0x3dae 0x3b37 0x3a09 0x39a6 0x3997 0x3d90 0x3b2f 0x3a06 0x39a3 0x3994 0x3d6d 0x3b29 0x3a00 0x39a0 0x3991 0x3d4a 0x3b20 0x39f8 0x399b 0x398c 0x3d30 0x3b11 0x39f5 0x3997 0x3989 0x3d1e 0x3b08 0x39f6 0x399b 0x398a 0x3d0f 0x3b08 0x39f7 0x39a7 0x3994 0x3d04 0x3b0b 0x3a01 0x39b2 0x399f 0x3cfa 0x3b0e 0x3a1d 0x39bd 0x39a8 0x3cf2 0x3b16 0x3a31 0x39c6 0x39b1 0x3cea 0x3b20 0x3a38 0x39cb 0x39b7 0x3ce3 0x3b2e 0x3a3d 0x39d0 0x39bc 0x3cdf 0x3b43 0x3a3c 0x39d1 0x39bd 0x3cdf 0x3b50 0x3a36 0x39cd 0x39ba 0x3cde 0x3b51 0x3a2f 0x39c8 0x39b4 0x3cdf 0x3b51 0x3a2a 0x39c4 0x39af 0x3ce6 0x3b50 0x3a25 0x39c1 0x39ab 0x3ced 0x3b4b 0x3a22 0x39bd 0x39a7 0x3cef 0x3b45 0x3a1f 0x39b8 0x39a3 0x3cf0 0x3b3f 0x3a1d 0x39b3 0x399f 0x3cf0 0x3b37 0x3a1c 0x39b1 0x399c 0x3cef 0x3b32 0x3a1a 0x39b0 0x3999 0x3cec 0x3b30 0x3a19 0x39b0 0x3998 0x3ce8 0x3b2e 0x3a19 0x39af 0x3998 0x3ce3 0x3b2e 0x3a19 0x39ae 0x3999 0x3cdd 0x3b32 0x3a1a 0x39af 0x399a 0x3cdb 0x3b37 0x3a1e 0x39b3 0x399d 0x3cde 0x3b3b 0x3a20 0x39b5 0x39a0 0x3ce2 0x3b3e 0x3a1e 0x39b3 0x399f 0x3ce1 0x3b41 0x3a1d 0x39b2 0x399f 0x3cda 0x3b42 0x3a1d 0x39b4 0x39a2 0x3cc0 0x3b30 0x3a12 0x39ae 0x399d 0x3cba 0x3b29 0x3a0b 0x39a5 0x3994 0x3cbb 0x3b25 0x3a04 0x39a0 0x398e 0x3cbd 0x3b1f 0x3a00 0x3999 0x3987 0x3cbd 0x3b1d 0x39f9 0x3993 0x397f 0x3cc1 0x3b20 0x39fa 0x3992 0x397e 0x3ccf 0x3b2d 0x3a09 0x39a1 0x3991 0x3ce6 0x3b48 0x3a13 0x39a8 0x3997 0x3cfe 0x3b59 0x3a18 0x39ac 0x399c 0x3d23 0x3b72 0x3a23 0x39b2 0x39a0 0x3d23 0x3b72 0x3a23 0x39b2 0x39a0 0x3d23 0x3b72 0x3a23 0x39b2 0x39a0>;
	};

	qcom,pc-temp-y1-lut {
		qcom,lut-col-legend = <0xfffffff6 0x00 0x0a 0x19 0x28 0x32>;
		qcom,lut-row-legend = <0x2710 0x2648 0x2580 0x24b8 0x23f0 0x2328 0x2260 0x2198 0x20d0 0x2008 0x1f40 0x1e78 0x1db0 0x1ce8 0x1c20 0x1b58 0x1a90 0x19c8 0x1900 0x1838 0x1770 0x16a8 0x15e0 0x1518 0x1450 0x1388 0x12c0 0x11f8 0x1130 0x1068 0xfa0 0xed8 0xe10 0xd48 0xc80 0xbb8 0xaf0 0xa28 0x960 0x898 0x7d0 0x708 0x640 0x578 0x4b0 0x3e8 0x384 0x320 0x2bc 0x258 0x1f4 0x190 0x12c 0xc8 0x64 0x00>;
		qcom,lut-data = <0x1c0d 0x19fe 0x1840 0x16ed 0x1642 0x1615 0x1bf8 0x19fd 0x185c 0x16f0 0x1641 0x1615 0x1be5 0x19fc 0x1870 0x16f2 0x1641 0x1615 0x1bd5 0x19fa 0x187d 0x16f3 0x1640 0x1616 0x1bca 0x19f9 0x1885 0x16f3 0x163f 0x1616 0x1bc5 0x19f9 0x1887 0x16f3 0x163f 0x1616 0x1bc8 0x19fb 0x1883 0x16f2 0x163e 0x1616 0x1bcf 0x19ff 0x187b 0x16f0 0x163d 0x1616 0x1bd0 0x1a00 0x1878 0x16ef 0x163d 0x1616 0x1bca 0x19ff 0x1877 0x16ef 0x163d 0x1616 0x1bc6 0x19fe 0x1877 0x16ee 0x163c 0x1617 0x1bd0 0x1a00 0x1879 0x16ed 0x163c 0x1617 0x1be7 0x1a04 0x187f 0x16eb 0x163c 0x1616 0x1bf3 0x1a0b 0x1881 0x16eb 0x163c 0x1616 0x1bed 0x1a1e 0x1882 0x16ed 0x163c 0x1618 0x1be3 0x1a31 0x1883 0x16f1 0x163c 0x1619 0x1bdc 0x1a31 0x1884 0x16f4 0x163d 0x161a 0x1bd6 0x1a27 0x1886 0x16f6 0x163f 0x161c 0x1bd4 0x1a1f 0x1888 0x16f8 0x1641 0x161d 0x1bd7 0x1a1c 0x188a 0x16f9 0x1642 0x161f 0x1bdb 0x1a1a 0x188c 0x16fa 0x1644 0x1621 0x1be0 0x1a1a 0x188e 0x16fc 0x1646 0x1623 0x1bf1 0x1a1a 0x1891 0x16ff 0x1648 0x1625 0x1bfd 0x1a1c 0x1892 0x1702 0x164a 0x1627 0x1bfa 0x1a22 0x1894 0x1708 0x164d 0x1629 0x1bf1 0x1a2a 0x1896 0x170d 0x1650 0x162a 0x1be9 0x1a2a 0x1897 0x1710 0x1653 0x162d 0x1be2 0x1a24 0x1899 0x1713 0x1656 0x1630 0x1bdd 0x1a1f 0x189b 0x1715 0x1659 0x1634 0x1bde 0x1a20 0x189f 0x1718 0x165c 0x1637 0x1bdf 0x1a25 0x18a6 0x171b 0x165f 0x1639 0x1be0 0x1a28 0x18ad 0x1721 0x1662 0x163b 0x1be0 0x1a2b 0x18b5 0x172a 0x1666 0x163f 0x1bdf 0x1a2d 0x18bb 0x1731 0x1668 0x1641 0x1be7 0x1a30 0x18b9 0x1732 0x166b 0x1643 0x1bff 0x1a33 0x18b2 0x1734 0x166d 0x1645 0x1c0b 0x1a34 0x18af 0x1736 0x1670 0x1647 0x1c03 0x1a33 0x18b1 0x1739 0x1672 0x1649 0x1bf7 0x1a35 0x18b3 0x173e 0x1675 0x164c 0x1bf5 0x1a37 0x18b5 0x1741 0x1677 0x164e 0x1bf9 0x1a39 0x18b7 0x1745 0x1679 0x164f 0x1bfd 0x1a3d 0x18bb 0x1748 0x167b 0x1651 0x1c05 0x1a4d 0x18ce 0x174c 0x167f 0x1654 0x1c17 0x1a5c 0x18d8 0x1751 0x1683 0x1657 0x1c10 0x1a45 0x18c7 0x175c 0x1687 0x165b 0x1c12 0x1a3d 0x18ca 0x176c 0x168f 0x165c 0x1c24 0x1a50 0x18d3 0x176c 0x1691 0x165c 0x1c41 0x1a62 0x18d4 0x1765 0x168f 0x165d 0x1c6c 0x1a55 0x18d6 0x1771 0x168e 0x165c 0x1c76 0x1a5c 0x18db 0x1769 0x1690 0x165d 0x1c81 0x1a5f 0x18f1 0x1770 0x1692 0x1660 0x1cbb 0x1a77 0x18f3 0x1778 0x1699 0x1666 0x1cfb 0x1aa2 0x18ff 0x1793 0x16a6 0x166e 0x1d36 0x1ace 0x1916 0x17ad 0x16b4 0x1677 0x1d36 0x1ace 0x1916 0x17ad 0x16b4 0x1677 0x1d36 0x1ace 0x1916 0x17ad 0x16b4 0x1677>;
	};

	qcom,pc-temp-y2-lut {
		qcom,lut-col-legend = <0xfffffff6 0x00 0x0a 0x19 0x28 0x32>;
		qcom,lut-row-legend = <0x2710 0x2648 0x2580 0x24b8 0x23f0 0x2328 0x2260 0x2198 0x20d0 0x2008 0x1f40 0x1e78 0x1db0 0x1ce8 0x1c20 0x1b58 0x1a90 0x19c8 0x1900 0x1838 0x1770 0x16a8 0x15e0 0x1518 0x1450 0x1388 0x12c0 0x11f8 0x1130 0x1068 0xfa0 0xed8 0xe10 0xd48 0xc80 0xbb8 0xaf0 0xa28 0x960 0x898 0x7d0 0x708 0x640 0x578 0x4b0 0x3e8 0x384 0x320 0x2bc 0x258 0x1f4 0x190 0x12c 0xc8 0x64 0x00>;
		qcom,lut-data = <0x25ab 0x2afe 0x2b47 0x2d34 0x2c73 0x2c1a 0x25b1 0x2975 0x2b2f 0x2d08 0x2c6c 0x2c04 0x25c6 0x2883 0x2b14 0x2cda 0x2c54 0x2be8 0x25d5 0x2803 0x2af9 0x2cae 0x2c33 0x2bcc 0x25de 0x27d1 0x2ae2 0x2c86 0x2c12 0x2bb7 0x25e1 0x27c8 0x2ad0 0x2c65 0x2bfa 0x2bad 0x25db 0x2853 0x2ac5 0x2c49 0x2be5 0x2bb2 0x25cf 0x296e 0x2abc 0x2c31 0x2bcd 0x2bbc 0x25cc 0x29bf 0x2aaf 0x2c1d 0x2bc7 0x2bbd 0x25d0 0x2946 0x2a91 0x2c08 0x2bd6 0x2ba9 0x25d4 0x28d4 0x2a7a 0x2bf3 0x2be2 0x2b93 0x25d3 0x2908 0x2af9 0x2bd5 0x2bd3 0x2b85 0x25cf 0x29bf 0x2c20 0x2bae 0x2bb3 0x2b73 0x25cb 0x2a63 0x2c8b 0x2ba8 0x2ba9 0x2b6d 0x25c9 0x2adb 0x2c73 0x2c0a 0x2bd4 0x2b7c 0x25c7 0x2b4a 0x2c5b 0x2c8e 0x2c1b 0x2b96 0x25c6 0x2bbf 0x2c6d 0x2ced 0x2c70 0x2bda 0x25c6 0x2c3c 0x2caf 0x2d42 0x2ce1 0x2c5f 0x25c5 0x2c72 0x2ce3 0x2d70 0x2d29 0x2c94 0x25c5 0x2c19 0x2cfe 0x2d83 0x2d4f 0x2c7e 0x25c4 0x2b58 0x2d14 0x2d91 0x2d69 0x2c65 0x25c3 0x2a1d 0x2d2f 0x2da1 0x2d78 0x2c75 0x25c3 0x279c 0x2d4f 0x2db2 0x2d86 0x2cc2 0x25c2 0x2606 0x2d5e 0x2dc8 0x2d8e 0x2d01 0x25c2 0x25f5 0x2d4b 0x2df8 0x2d92 0x2d17 0x25c2 0x25ef 0x2d32 0x2e31 0x2d9a 0x2d29 0x25c1 0x25e8 0x2d32 0x2e56 0x2db3 0x2d4a 0x25c0 0x25e0 0x2d46 0x2e72 0x2dfb 0x2d7d 0x25c0 0x25d9 0x2d54 0x2e82 0x2e3c 0x2da0 0x25bf 0x25d4 0x2cd7 0x2e8c 0x2e51 0x2db1 0x25bf 0x25d1 0x2bd3 0x2e94 0x2e60 0x2dc7 0x25be 0x25cd 0x2b7d 0x2e95 0x2e7a 0x2de9 0x25be 0x25ca 0x2bf5 0x2e8f 0x2ead 0x2e34 0x25be 0x25c7 0x2c61 0x2e86 0x2ece 0x2e63 0x25be 0x25c5 0x2c37 0x2e74 0x2ea1 0x2e40 0x25bd 0x25c3 0x2bea 0x2e58 0x2e38 0x2df1 0x25bd 0x25c2 0x2b9e 0x2e36 0x2e04 0x2dcd 0x25bd 0x25c0 0x2b5e 0x2dfd 0x2df4 0x2dc6 0x25bd 0x25bf 0x2b02 0x2dba 0x2de8 0x2dbe 0x25bd 0x25be 0x29bc 0x2d81 0x2dd5 0x2daf 0x25bc 0x25bd 0x2790 0x2d48 0x2dba 0x2da0 0x25bc 0x25bd 0x2679 0x2d00 0x2da5 0x2d99 0x25bc 0x25bc 0x2617 0x2c97 0x2d80 0x2d79 0x25bc 0x25bb 0x25e7 0x2c23 0x2d52 0x2d34 0x25bb 0x25bb 0x25d8 0x2bab 0x2d24 0x2c97 0x25ba 0x25ba 0x25d0 0x2b67 0x2cc6 0x2c29 0x25b9 0x25ba 0x25d0 0x2b70 0x2c9c 0x2c25 0x25b9 0x25ba 0x25d5 0x2b98 0x2cc9 0x2c49 0x25b9 0x25ba 0x25d3 0x2b90 0x2cfc 0x2cb5 0x25b8 0x25ba 0x25d2 0x2b96 0x2cec 0x2cbb 0x25b6 0x25ba 0x25cf 0x2b56 0x2cc2 0x2c3e 0x25b5 0x25b9 0x25ca 0x2acc 0x2c3e 0x2bb9 0x25b4 0x25b7 0x25c4 0x2a27 0x2bfd 0x2b4c 0x25b2 0x25b5 0x25be 0x2991 0x2b69 0x2ac1 0x25b2 0x25b5 0x25be 0x2991 0x2b69 0x2ac1 0x25b2 0x25b5 0x25be 0x2991 0x2b69 0x2ac1>;
	};

	qcom,pc-temp-y3-lut {
		qcom,lut-col-legend = <0xfffffff6 0x00 0x0a 0x19 0x28 0x32>;
		qcom,lut-row-legend = <0x2710 0x2648 0x2580 0x24b8 0x23f0 0x2328 0x2260 0x2198 0x20d0 0x2008 0x1f40 0x1e78 0x1db0 0x1ce8 0x1c20 0x1b58 0x1a90 0x19c8 0x1900 0x1838 0x1770 0x16a8 0x15e0 0x1518 0x1450 0x1388 0x12c0 0x11f8 0x1130 0x1068 0xfa0 0xed8 0xe10 0xd48 0xc80 0xbb8 0xaf0 0xa28 0x960 0x898 0x7d0 0x708 0x640 0x578 0x4b0 0x3e8 0x384 0x320 0x2bc 0x258 0x1f4 0x190 0x12c 0xc8 0x64 0x00>;
		qcom,lut-data = <0x367a 0x34fe 0x341a 0x33f2 0x33df 0x33dc 0x3661 0x34e6 0x3423 0x33f2 0x33df 0x33db 0x363e 0x34d7 0x342b 0x33f2 0x33e0 0x33dc 0x3613 0x34cf 0x3433 0x33f3 0x33e1 0x33dc 0x35df 0x34cc 0x3438 0x33f3 0x33e2 0x33dd 0x35a6 0x34cb 0x343b 0x33f4 0x33e2 0x33dd 0x3555 0x34e2 0x3439 0x33f5 0x33e2 0x33de 0x34ff 0x3511 0x3437 0x33f6 0x33e2 0x33de 0x34e7 0x3516 0x3437 0x33f7 0x33e3 0x33de 0x34ee 0x34ab 0x343d 0x33f8 0x33e3 0x33e0 0x34f6 0x3446 0x3442 0x33f9 0x33e4 0x33e1 0x34f9 0x344b 0x343a 0x33fc 0x33e4 0x33e1 0x34f7 0x346a 0x3428 0x3400 0x33e4 0x33e1 0x34ef 0x3476 0x3422 0x3401 0x33e4 0x33e1 0x34cb 0x3467 0x3425 0x33fc 0x33e6 0x33e1 0x34a6 0x3452 0x3428 0x33f6 0x33e8 0x33e1 0x34a3 0x3445 0x3426 0x33f6 0x33e9 0x33e2 0x34a7 0x343c 0x341f 0x33f8 0x33ea 0x33e5 0x34a9 0x3434 0x3418 0x33f9 0x33ea 0x33e6 0x34a7 0x342e 0x3414 0x33f6 0x33e8 0x33e4 0x34a3 0x3427 0x340f 0x33f1 0x33e5 0x33e0 0x34a2 0x341a 0x340c 0x33ee 0x33e3 0x33df 0x34a3 0x33ff 0x3409 0x33eb 0x33e1 0x33dd 0x34a5 0x33ed 0x3407 0x33ea 0x33e0 0x33dc 0x34ad 0x33ee 0x3404 0x33ea 0x33df 0x33dc 0x34bd 0x33f2 0x3401 0x33e9 0x33df 0x33dc 0x34cf 0x33f7 0x33fe 0x33e9 0x33de 0x33dc 0x34e8 0x3402 0x33fb 0x33e9 0x33dd 0x33db 0x3504 0x3410 0x33f9 0x33e9 0x33dd 0x33da 0x351c 0x341f 0x33f6 0x33e9 0x33dd 0x33db 0x3533 0x3431 0x33f2 0x33e9 0x33de 0x33db 0x354c 0x3443 0x33f2 0x33e9 0x33de 0x33db 0x3567 0x3457 0x33fa 0x33e9 0x33df 0x33dc 0x3583 0x346d 0x3403 0x33e9 0x33df 0x33dc 0x359f 0x3487 0x3407 0x33e9 0x33df 0x33dc 0x35bd 0x34a3 0x340a 0x33eb 0x33df 0x33db 0x35dc 0x34c2 0x340e 0x33eb 0x33de 0x33db 0x35fb 0x34e3 0x3411 0x33ea 0x33de 0x33db 0x361b 0x3506 0x3415 0x33e9 0x33dd 0x33db 0x363f 0x352d 0x3419 0x33eb 0x33dd 0x33db 0x3666 0x3557 0x341d 0x33ee 0x33dd 0x33dc 0x3690 0x3583 0x3423 0x33f0 0x33dd 0x33dc 0x36ba 0x35b0 0x3430 0x33f0 0x33de 0x33dc 0x36e9 0x35df 0x3445 0x33f0 0x33df 0x33dc 0x3728 0x360c 0x3463 0x33f2 0x33e0 0x33db 0x3796 0x3639 0x3494 0x33fa 0x33e5 0x33e1 0x37d8 0x3648 0x3498 0x33fc 0x33e6 0x33e3 0x37a0 0x3620 0x348c 0x33fd 0x33e8 0x33e4 0x37b9 0x362a 0x34a3 0x3403 0x33eb 0x33e6 0x387f 0x3664 0x34b9 0x3407 0x33eb 0x33e6 0x396d 0x3698 0x34ce 0x3407 0x33e8 0x33e1 0x3aba 0x36e9 0x34ea 0x3406 0x33e8 0x33e1 0x3cd0 0x37cc 0x3520 0x340d 0x33eb 0x33e3 0x3fe9 0x396d 0x35b8 0x3420 0x33f1 0x33ea 0x3fe9 0x396d 0x35b8 0x3420 0x33f1 0x33ea 0x3fe9 0x396d 0x35b8 0x3420 0x33f1 0x33ea>;
	};

	qcom,pc-temp-y4-lut {
		qcom,lut-col-legend = <0xfffffff6 0x00 0x0a 0x19 0x28 0x32>;
		qcom,lut-row-legend = <0x2710 0x2648 0x2580 0x24b8 0x23f0 0x2328 0x2260 0x2198 0x20d0 0x2008 0x1f40 0x1e78 0x1db0 0x1ce8 0x1c20 0x1b58 0x1a90 0x19c8 0x1900 0x1838 0x1770 0x16a8 0x15e0 0x1518 0x1450 0x1388 0x12c0 0x11f8 0x1130 0x1068 0xfa0 0xed8 0xe10 0xd48 0xc80 0xbb8 0xaf0 0xa28 0x960 0x898 0x7d0 0x708 0x640 0x578 0x4b0 0x3e8 0x384 0x320 0x2bc 0x258 0x1f4 0x190 0x12c 0xc8 0x64 0x00>;
		qcom,lut-data = <0x4371 0x4030 0x4148 0x4073 0x4047 0x4045 0x431d 0x414c 0x414f 0x4073 0x4045 0x4042 0x42f7 0x41ff 0x4159 0x4073 0x4044 0x4040 0x42f4 0x4260 0x4163 0x4073 0x4044 0x403f 0x430b 0x4289 0x416c 0x4074 0x4044 0x403f 0x4332 0x4292 0x4171 0x4075 0x4045 0x403f 0x437e 0x4257 0x4173 0x4075 0x4046 0x403f 0x43f8 0x41dd 0x4174 0x4077 0x4048 0x4040 0x445d 0x41cd 0x4174 0x4078 0x404a 0x4041 0x44bc 0x42e0 0x4172 0x407c 0x404d 0x4043 0x44f8 0x43e4 0x4171 0x4082 0x4050 0x4044 0x4474 0x43c6 0x41ab 0x408b 0x4055 0x4047 0x42fb 0x4336 0x4232 0x4098 0x405b 0x404b 0x4242 0x42ae 0x425a 0x40a4 0x4062 0x4050 0x4231 0x422b 0x41cd 0x40ab 0x4067 0x4056 0x4225 0x41c8 0x413e 0x40b4 0x406d 0x405e 0x4210 0x41b6 0x4134 0x40c5 0x407a 0x406a 0x41ed 0x41b3 0x4138 0x40e1 0x4091 0x407a 0x41c6 0x41ac 0x4139 0x40eb 0x409a 0x4080 0x4197 0x418a 0x4120 0x40c8 0x408d 0x4079 0x416c 0x4157 0x40fc 0x4099 0x4078 0x406d 0x415f 0x4134 0x40e6 0x4080 0x4065 0x405f 0x4159 0x4117 0x40d7 0x406d 0x4050 0x404d 0x4157 0x4109 0x40cb 0x4065 0x4046 0x4043 0x4159 0x410a 0x40c1 0x4064 0x4046 0x4041 0x415c 0x410d 0x40b8 0x4063 0x4047 0x4040 0x415e 0x410d 0x40a7 0x4064 0x4048 0x4041 0x415e 0x410c 0x408b 0x4068 0x404e 0x4046 0x415e 0x410b 0x407a 0x406c 0x4055 0x404d 0x4162 0x410e 0x4083 0x4072 0x405d 0x4054 0x416c 0x4114 0x4094 0x4077 0x4066 0x405c 0x4176 0x411b 0x409d 0x4078 0x406c 0x4064 0x417d 0x4122 0x40a0 0x4076 0x4071 0x406d 0x4184 0x4129 0x40a5 0x4074 0x4074 0x4072 0x4191 0x412e 0x40af 0x4071 0x406f 0x406c 0x41a2 0x4133 0x40c1 0x406d 0x4062 0x405d 0x41b4 0x4135 0x40d1 0x406c 0x4058 0x4052 0x41c5 0x4135 0x40df 0x406c 0x4050 0x404a 0x41d8 0x4135 0x40ea 0x406c 0x404b 0x4046 0x41f0 0x4135 0x40f1 0x4070 0x404d 0x4048 0x4210 0x4135 0x40f5 0x4078 0x4052 0x404f 0x4233 0x4137 0x40fb 0x407d 0x4055 0x4051 0x4257 0x4145 0x4104 0x4080 0x404f 0x4049 0x427c 0x4161 0x4116 0x4083 0x404a 0x4042 0x42a4 0x418b 0x4140 0x4089 0x404a 0x4041 0x42cc 0x41c5 0x418f 0x40a7 0x405a 0x4053 0x42d9 0x41dc 0x419f 0x40ac 0x406d 0x4069 0x4272 0x41bb 0x4189 0x40b4 0x407e 0x407f 0x4249 0x41b2 0x41af 0x40d7 0x409a 0x409c 0x42a0 0x41c7 0x41d4 0x40f4 0x40a0 0x4097 0x430f 0x41cb 0x41f3 0x40e2 0x4071 0x405c 0x43c2 0x41c8 0x41ff 0x40bf 0x405e 0x4050 0x453c 0x4241 0x41fe 0x40ce 0x4066 0x4054 0x48a8 0x4362 0x4263 0x40f9 0x407a 0x4063 0x48a8 0x4362 0x4263 0x40f9 0x407a 0x4063 0x48a8 0x4362 0x4263 0x40f9 0x407a 0x4063>;
	};

	qcom,pc-temp-y5-lut {
		qcom,lut-col-legend = <0xfffffff6 0x00 0x0a 0x19 0x28 0x32>;
		qcom,lut-row-legend = <0x2710 0x2648 0x2580 0x24b8 0x23f0 0x2328 0x2260 0x2198 0x20d0 0x2008 0x1f40 0x1e78 0x1db0 0x1ce8 0x1c20 0x1b58 0x1a90 0x19c8 0x1900 0x1838 0x1770 0x16a8 0x15e0 0x1518 0x1450 0x1388 0x12c0 0x11f8 0x1130 0x1068 0xfa0 0xed8 0xe10 0xd48 0xc80 0xbb8 0xaf0 0xa28 0x960 0x898 0x7d0 0x708 0x640 0x578 0x4b0 0x3e8 0x384 0x320 0x2bc 0x258 0x1f4 0x190 0x12c 0xc8 0x64 0x00>;
		qcom,lut-data = <0x2208 0x3add 0x352d 0x4fee 0x4c81 0x4731 0x29e3 0x399d 0x3906 0x4f61 0x4ef5 0x4ce5 0x3017 0x3903 0x3d25 0x4ea4 0x5011 0x4fa8 0x3369 0x38fb 0x40eb 0x4dc9 0x5021 0x5072 0x34c1 0x3972 0x43ba 0x4ce2 0x4f72 0x5037 0x3502 0x3a55 0x44f2 0x4c01 0x4e53 0x4ff0 0x32ea 0x45b4 0x449c 0x4b30 0x4bcf 0x4ec8 0x2e9e 0x5b7f 0x4398 0x4a47 0x4800 0x4c1c 0x2e0f 0x6092 0x41d6 0x48f5 0x45a6 0x4b2b 0x38cf 0x4b30 0x3cd8 0x469a 0x4472 0x4c02 0x44ae 0x36ec 0x38da 0x444e 0x433d 0x4c35 0x4849 0x3e86 0x39cd 0x42f3 0x40e7 0x4a1c 0x4950 0x55ef 0x3d7b 0x41e2 0x3deb 0x46ba 0x47e1 0x5f86 0x42da 0x4090 0x3cf0 0x4365 0x3fd9 0x5579 0x4f4c 0x3e4a 0x3d78 0x3f8b 0x37de 0x49f0 0x59f9 0x3c9c 0x3e72 0x3ccc 0x3802 0x49e9 0x5a26 0x3ea6 0x3fcd 0x3dab 0x3b61 0x4f44 0x5826 0x4578 0x420d 0x413a 0x3d40 0x5446 0x5773 0x4c52 0x453d 0x44d9 0x3ba0 0x580d 0x5820 0x5414 0x4c8d 0x48b5 0x389f 0x5ae1 0x5905 0x5a08 0x5425 0x4d1e 0x361d 0x574d 0x59cd 0x593d 0x568f 0x51c7 0x33b2 0x4258 0x5b20 0x54d2 0x57f2 0x56f6 0x323d 0x32fe 0x5c6a 0x52a8 0x5889 0x593b 0x31a2 0x31cf 0x5d8f 0x5310 0x5630 0x57e2 0x3121 0x3155 0x5e75 0x53cc 0x51e1 0x5510 0x3115 0x3177 0x5d22 0x54a7 0x4e7d 0x5157 0x31e3 0x326d 0x55a3 0x55a3 0x4b3e 0x4b7f 0x3298 0x3379 0x4db3 0x55fb 0x498a 0x4839 0x3265 0x3406 0x4690 0x56d4 0x4a52 0x487b 0x31d5 0x346f 0x3fbb 0x58be 0x4c61 0x4942 0x31a1 0x34e1 0x3f20 0x5b0b 0x4f19 0x4aa7 0x31ef 0x3585 0x478b 0x5ee5 0x5392 0x4e70 0x3241 0x3649 0x4f35 0x6232 0x5806 0x5273 0x320f 0x371a 0x50d5 0x643a 0x5ba7 0x5542 0x3184 0x380c 0x51c0 0x65b3 0x5f06 0x577d 0x3152 0x38b2 0x523a 0x646a 0x5fd1 0x5834 0x318c 0x38fc 0x52c7 0x5995 0x5b0c 0x583f 0x31f5 0x38ec 0x5292 0x50be 0x54a1 0x57e7 0x325f 0x3860 0x4deb 0x5129 0x5079 0x5642 0x32d8 0x376b 0x4483 0x529c 0x4cfb 0x535e 0x3355 0x3695 0x3e27 0x5251 0x4c36 0x52c7 0x3402 0x35df 0x3a4e 0x4cf3 0x4fdd 0x571f 0x3526 0x35a5 0x386e 0x48b1 0x51ee 0x576f 0x36b1 0x362c 0x378d 0x4527 0x4f08 0x49fb 0x38a0 0x3670 0x370a 0x4364 0x4ae3 0x4884 0x3a5a 0x36cf 0x3785 0x4518 0x4706 0x45bc 0x3b35 0x3921 0x3b92 0x46d4 0x4710 0x4508 0x3b2f 0x3cf8 0x403c 0x48de 0x47c2 0x4583 0x39c0 0x3f6a 0x4491 0x4bd5 0x48dc 0x45c7 0x3611 0x4068 0x474e 0x4fa3 0x4e32 0x485e 0x3180 0x3b2f 0x4647 0x4d55 0x523e 0x4a08 0x2cdd 0x326a 0x3fc9 0x4a4b 0x54d2 0x4888 0x2872 0x2c9b 0x3507 0x4a5e 0x5d6e 0x5bca 0x2872 0x2c9b 0x3507 0x4a5e 0x5d6e 0x5bca 0x2872 0x2c9b 0x3507 0x4a5e 0x5d6e 0x5bca>;
	};

	qcom,pc-temp-y6-lut {
		qcom,lut-col-legend = <0xfffffff6 0x00 0x0a 0x19 0x28 0x32>;
		qcom,lut-row-legend = <0x2710 0x2648 0x2580 0x24b8 0x23f0 0x2328 0x2260 0x2198 0x20d0 0x2008 0x1f40 0x1e78 0x1db0 0x1ce8 0x1c20 0x1b58 0x1a90 0x19c8 0x1900 0x1838 0x1770 0x16a8 0x15e0 0x1518 0x1450 0x1388 0x12c0 0x11f8 0x1130 0x1068 0xfa0 0xed8 0xe10 0xd48 0xc80 0xbb8 0xaf0 0xa28 0x960 0x898 0x7d0 0x708 0x640 0x578 0x4b0 0x3e8 0x384 0x320 0x2bc 0x258 0x1f4 0x190 0x12c 0xc8 0x64 0x00>;
		qcom,lut-data = <0x19b5 0x16c8 0x1500 0x1406 0x13cc 0x13c4 0x1989 0x16c8 0x1503 0x1406 0x13cd 0x13c4 0x195f 0x16c6 0x1506 0x1406 0x13cd 0x13c4 0x1937 0x16c3 0x1506 0x1406 0x13ce 0x13c4 0x1910 0x16bf 0x1506 0x1406 0x13ce 0x13c5 0x18eb 0x16b9 0x1506 0x1406 0x13cf 0x13c5 0x18c1 0x16b0 0x1502 0x1407 0x13cf 0x13c6 0x189a 0x16a6 0x14fd 0x1408 0x13d0 0x13c6 0x1891 0x16a4 0x14fb 0x1409 0x13d1 0x13c7 0x18ac 0x16ab 0x14fa 0x140a 0x13d2 0x13c8 0x18c6 0x16b1 0x14fa 0x140b 0x13d3 0x13ca 0x18a4 0x16ad 0x1504 0x1410 0x13d5 0x13cb 0x183a 0x169c 0x151b 0x1417 0x13d7 0x13cc 0x17f9 0x1686 0x1521 0x1419 0x13d9 0x13ce 0x17e3 0x165e 0x14ff 0x1419 0x13db 0x13d0 0x17d5 0x163a 0x14da 0x1418 0x13df 0x13d2 0x17ce 0x1632 0x14d3 0x141b 0x13e4 0x13d6 0x17c9 0x1630 0x14d0 0x1425 0x13eb 0x13dc 0x17c4 0x162d 0x14cd 0x1429 0x13ed 0x13df 0x17bb 0x1624 0x14c3 0x141c 0x13e8 0x13dc 0x17b2 0x1619 0x14b7 0x140c 0x13e0 0x13d6 0x17b1 0x160c 0x14b0 0x1403 0x13d8 0x13d0 0x17b3 0x15fc 0x14aa 0x13fc 0x13d1 0x13ca 0x17b6 0x15f3 0x14a7 0x13f9 0x13ce 0x13c7 0x17bf 0x15fb 0x14a7 0x13f9 0x13ce 0x13c6 0x17ce 0x160e 0x14a6 0x13fa 0x13cd 0x13c6 0x17df 0x1620 0x14a4 0x13fa 0x13ce 0x13c6 0x17f2 0x1633 0x149e 0x13fc 0x13cf 0x13c7 0x1806 0x1648 0x149b 0x13fe 0x13d2 0x13c9 0x181b 0x165c 0x149f 0x1400 0x13d4 0x13cc 0x1830 0x1671 0x14a9 0x1403 0x13d7 0x13cf 0x1846 0x168a 0x14b4 0x1404 0x13da 0x13d1 0x185b 0x16a8 0x14c3 0x1405 0x13dc 0x13d4 0x1872 0x16c8 0x14d4 0x1405 0x13dd 0x13d6 0x188c 0x16e8 0x14e7 0x1406 0x13dc 0x13d5 0x18a9 0x1707 0x14fd 0x1406 0x13d9 0x13d0 0x18c6 0x1727 0x1514 0x1407 0x13d6 0x13cd 0x18e3 0x1747 0x152c 0x1408 0x13d3 0x13cb 0x1901 0x1767 0x1545 0x140a 0x13d2 0x13ca 0x1924 0x178b 0x155e 0x140e 0x13d2 0x13cb 0x194c 0x17b3 0x1576 0x1415 0x13d5 0x13ce 0x1977 0x17dd 0x1594 0x141b 0x13d6 0x13ce 0x19a2 0x1808 0x15ba 0x141f 0x13d5 0x13cc 0x19d4 0x1837 0x15ea 0x1424 0x13d5 0x13ca 0x1a18 0x1867 0x1629 0x142e 0x13d7 0x13cb 0x1a98 0x189f 0x167c 0x1443 0x13e0 0x13d4 0x1ae4 0x18b5 0x1682 0x1446 0x13e6 0x13dc 0x1aa2 0x1894 0x1666 0x1447 0x13ec 0x13e3 0x1ac1 0x189b 0x1689 0x1458 0x13f6 0x13ed 0x1ba2 0x18d0 0x16ab 0x1465 0x13f8 0x13eb 0x1cad 0x18fe 0x16cf 0x1461 0x13e9 0x13d8 0x1e21 0x194b 0x16fb 0x145e 0x13e5 0x13d5 0x208d 0x1a61 0x1743 0x1478 0x13eb 0x13d9 0x2459 0x1c50 0x1806 0x14ab 0x13f8 0x13e3 0x2459 0x1c50 0x1806 0x14ab 0x13f8 0x13e3 0x2459 0x1c50 0x1806 0x14ab 0x13f8 0x13e3>;
	};
};
